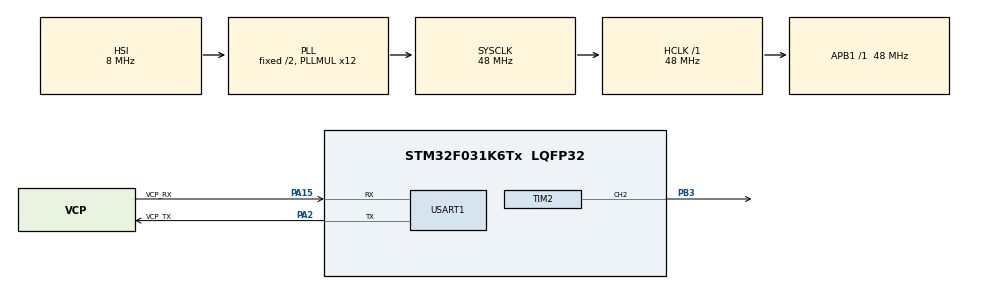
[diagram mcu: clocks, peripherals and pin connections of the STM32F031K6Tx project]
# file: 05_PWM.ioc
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Mcu.Family=STM32F0
NVIC.TIM14_IRQn=true\:0\:0\:false\:false\:true\:true\:true
PA14.GPIO_Label=SWCLK
TIM2.Channel-PWM\ Generation2\ CH2=TIM_CHANNEL_2
RCC.SYSCLKSource=RCC_SYSCLKSOURCE_PLLCLK
ProjectManager.StackSize=0x400
USART1.VirtualMode-Asynchronous=VM_ASYNC
PA13.Signal=SYS_SWDIO
SH.S_TIM2_CH2.0=TIM2_CH2,PWM Generation2 CH2
PA15.GPIO_Label=VCP_RX
ProjectManager.TargetToolchain=TrueSTUDIO
RCC.HCLKFreq_Value=48000000
RCC.AHBFreq_Value=48000000
PF0-OSC_IN.Mode=HSE-External-Clock-Source
board=NUCLEO-F031K6
TIM14.Period=191
PA15.Mode=Asynchronous
RCC.PLLMUL=RCC_PLL_MUL12
VP_TIM2_VS_ClockSourceINT.Mode=Internal
PA14.Mode=Serial_Wire
NVIC.TIM2_IRQn=true\:0\:0\:false\:false\:true\:true\:true
TIM2.Period=99
PA13.Mode=Serial_Wire
Mcu.Name=STM32F031K6Tx
TIM14.Prescaler=10000
PA2.Signal=USART1_TX
PA13.GPIO_Label=SWDIO
PB3.Signal=S_TIM2_CH2
RCC.SYSCLKFreq_VALUE=48000000
Mcu.Package=LQFP32
TIM2.Prescaler=4800
PA2.GPIO_Label=VCP_TX
PA14.Signal=SYS_SWCLK
PA15.Signal=USART1_RX
ProjectManager.HeapSize=0x200
RCC.APB1TimFreq_Value=48000000
PA2.Mode=Asynchronous
VP_TIM14_VS_ClockSourceINT.Mode=Enable_Timer
PF0-OSC_IN.Signal=RCC_OSC_IN
RCC.APB1Freq_Value=48000000

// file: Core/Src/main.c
/* USER CODE BEGIN Header */
/**
  ******************************************************************************
  * @file           : main.c
  * @brief          : Main program body
  ******************************************************************************
  * @attention
  *
  * <h2><center>&copy; Copyright (c) 2020 STMicroelectronics.
  * All rights reserved.</center></h2>
  *
  * This software component is licensed by ST under BSD 3-Clause license,
  * the "License"; You may not use this file except in compliance with the
  * License. You may obtain a copy of the License at:
  *                        opensource.org/licenses/BSD-3-Clause
  *
  ******************************************************************************
  */
/* USER CODE END Header */
#include "main.h"

TIM_HandleTypeDef htim2;
TIM_HandleTypeDef htim14;

UART_HandleTypeDef huart1;

void SystemClock_Config(void);
static void MX_GPIO_Init(void);
static void MX_USART1_UART_Init(void);
static void MX_TIM2_Init(void);
static void MX_TIM14_Init(void);
/* USER CODE BEGIN PFP */
//void HAL_SYSTICK_Callback(void) {
//	static uint8_t InterruptPrescaller = 0;
//	static uint8_t CzyRosnie = 1;
//
//	++InterruptPrescaller;
//
//	if (InterruptPrescaller == 40) {
//		InterruptPrescaller = 0;
//
//		if (Duty == 100) {
//			CzyRosnie = 0;
//		}
//		else if (Duty == 0) {
//			CzyRosnie = 1;
//		}
//
//		if (CzyRosnie == 1) {
//			++Duty;
//		}
//		else if (CzyRosnie == 0) {
//			--Duty;
//		}
//
//		TIM2->CCR2 = Duty;
//	}
//}

////Przerwanie wywolywane z czestotliwoscia 1KHz
//void HAL_SYSTICK_Callback(void) {
//	static uint8_t InterruptPrescaler = 0; // licznik przerwan
//	static uint8_t CzyRosnie = 1; // Flaga kierunku zliczania
//
//	++InterruptPrescaler; // Inkrementacja numeru przerwania
//
//	// Jezeli wywolalo sie 40 przerwanie z rzedu
//	if (InterruptPrescaler == 40) {
//		InterruptPrescaler = 0; // wyzeruj licznik przerwan
//
//		if (Duty == 100) // Jezeli wypelnienie jest rowne 100
//			CzyRosnie = 0; // Zmien kierunek zliczania w dol
//
//		else if (Duty == 0) // Jezeli wypelnienie rowne 0
//			CzyRosnie = 1; // Zmien kierunek zliczania w gore
//
//		if (CzyRosnie) // Jezeli zliczamy w gore
//			++Duty; // Inkrementuj wartosc wypelnienia
//		else//Jezeli zliczamy w dol
//			--Duty; // Dekrementuj wartosc wypelnienia
//	}
//	TIM2->CCR2 = Duty; // Wstawienie wyliczonej wartosci wypelnienia do
//	// rejestru timera odpowiedzialnego za wypelnienie generowanego sygnalu PWM
//}

void HAL_TIM_PeriodElapsedCallback(TIM_HandleTypeDef *htim) {
	static uint8_t Duty = 0;
	static uint8_t CzyRosnie = 1;
	if (htim->Instance == TIM14) {
		if (Duty == 100) {
			CzyRosnie = 0;
		}
		else if (Duty == 0) {
			CzyRosnie = 1;
		}

		if (CzyRosnie == 1) {
			++Duty;
		}
		else if (CzyRosnie == 0) {
			--Duty;
		}

		TIM2->CCR2 = Duty;
	}
}
/* USER CODE END PFP */

int main(void)
{

  /* MCU Configuration--------------------------------------------------------*/

  /* Reset of all peripherals, Initializes the Flash interface and the Systick. */
  HAL_Init();

  /* Configure the system clock */
  SystemClock_Config();

  /* Initialize all configured peripherals */
  MX_GPIO_Init();
  MX_USART1_UART_Init();
  MX_TIM2_Init();
  MX_TIM14_Init();
  /* USER CODE BEGIN 2 */
  HAL_TIM_PWM_Start(&htim2, TIM_CHANNEL_2);
  HAL_TIM_Base_Start_IT(&htim14);
  /* USER CODE END 2 */

  /* Infinite loop */
  while (1)
  {

  }
}

void SystemClock_Config(void)
{
  RCC_OscInitTypeDef RCC_OscInitStruct = {0};
  RCC_ClkInitTypeDef RCC_ClkInitStruct = {0};
  RCC_PeriphCLKInitTypeDef PeriphClkInit = {0};

  /** Initializes the RCC Oscillators according to the specified parameters
  * in the RCC_OscInitTypeDef structure.
  */
  RCC_OscInitStruct.OscillatorType = RCC_OSCILLATORTYPE_HSI;
  RCC_OscInitStruct.HSIState = RCC_HSI_ON;
  RCC_OscInitStruct.HSICalibrationValue = RCC_HSICALIBRATION_DEFAULT;
  RCC_OscInitStruct.PLL.PLLState = RCC_PLL_ON;
  RCC_OscInitStruct.PLL.PLLSource = RCC_PLLSOURCE_HSI;
  RCC_OscInitStruct.PLL.PLLMUL = RCC_PLL_MUL12;
  RCC_OscInitStruct.PLL.PREDIV = RCC_PREDIV_DIV1;
  if (HAL_RCC_OscConfig(&RCC_OscInitStruct) != HAL_OK)
  {
    Error_Handler();
  }
  /** Initializes the CPU, AHB and APB buses clocks
  */
  RCC_ClkInitStruct.ClockType = RCC_CLOCKTYPE_HCLK|RCC_CLOCKTYPE_SYSCLK
                              |RCC_CLOCKTYPE_PCLK1;
  RCC_ClkInitStruct.SYSCLKSource = RCC_SYSCLKSOURCE_PLLCLK;
  RCC_ClkInitStruct.AHBCLKDivider = RCC_SYSCLK_DIV1;
  RCC_ClkInitStruct.APB1CLKDivider = RCC_HCLK_DIV1;

  if (HAL_RCC_ClockConfig(&RCC_ClkInitStruct, FLASH_LATENCY_1) != HAL_OK)
  {
    Error_Handler();
  }
  PeriphClkInit.PeriphClockSelection = RCC_PERIPHCLK_USART1;
  PeriphClkInit.Usart1ClockSelection = RCC_USART1CLKSOURCE_PCLK1;
  if (HAL_RCCEx_PeriphCLKConfig(&PeriphClkInit) != HAL_OK)
  {
    Error_Handler();
  }
}

static void MX_TIM2_Init(void)
{

  TIM_ClockConfigTypeDef sClockSourceConfig = {0};
  TIM_MasterConfigTypeDef sMasterConfig = {0};
  TIM_OC_InitTypeDef sConfigOC = {0};

  htim2.Instance = TIM2;
  htim2.Init.Prescaler = 4800;
  htim2.Init.CounterMode = TIM_COUNTERMODE_UP;
  htim2.Init.Period = 99;
  htim2.Init.ClockDivision = TIM_CLOCKDIVISION_DIV1;
  htim2.Init.AutoReloadPreload = TIM_AUTORELOAD_PRELOAD_DISABLE;
  if (HAL_TIM_Base_Init(&htim2) != HAL_OK)
  {
    Error_Handler();
  }
  sClockSourceConfig.ClockSource = TIM_CLOCKSOURCE_INTERNAL;
  if (HAL_TIM_ConfigClockSource(&htim2, &sClockSourceConfig) != HAL_OK)
  {
    Error_Handler();
  }
  if (HAL_TIM_PWM_Init(&htim2) != HAL_OK)
  {
    Error_Handler();
  }
  sMasterConfig.MasterOutputTrigger = TIM_TRGO_RESET;
  sMasterConfig.MasterSlaveMode = TIM_MASTERSLAVEMODE_DISABLE;
  if (HAL_TIMEx_MasterConfigSynchronization(&htim2, &sMasterConfig) != HAL_OK)
  {
    Error_Handler();
  }
  sConfigOC.OCMode = TIM_OCMODE_PWM1;
  sConfigOC.Pulse = 0;
  sConfigOC.OCPolarity = TIM_OCPOLARITY_HIGH;
  sConfigOC.OCFastMode = TIM_OCFAST_DISABLE;
  if (HAL_TIM_PWM_ConfigChannel(&htim2, &sConfigOC, TIM_CHANNEL_2) != HAL_OK)
  {
    Error_Handler();
  }
  HAL_TIM_MspPostInit(&htim2);

}

static void MX_TIM14_Init(void)
{

  htim14.Instance = TIM14;
  htim14.Init.Prescaler = 10000;
  htim14.Init.CounterMode = TIM_COUNTERMODE_UP;
  htim14.Init.Period = 191;
  htim14.Init.ClockDivision = TIM_CLOCKDIVISION_DIV1;
  htim14.Init.AutoReloadPreload = TIM_AUTORELOAD_PRELOAD_DISABLE;
  if (HAL_TIM_Base_Init(&htim14) != HAL_OK)
  {
    Error_Handler();
  }

}

static void MX_USART1_UART_Init(void)
{

  huart1.Instance = USART1;
  huart1.Init.BaudRate = 38400;
  huart1.Init.WordLength = UART_WORDLENGTH_8B;
  huart1.Init.StopBits = UART_STOPBITS_1;
  huart1.Init.Parity = UART_PARITY_NONE;
  huart1.Init.Mode = UART_MODE_TX_RX;
  huart1.Init.HwFlowCtl = UART_HWCONTROL_NONE;
  huart1.Init.OverSampling = UART_OVERSAMPLING_16;
  huart1.Init.OneBitSampling = UART_ONE_BIT_SAMPLE_DISABLE;
  huart1.AdvancedInit.AdvFeatureInit = UART_ADVFEATURE_NO_INIT;
  if (HAL_UART_Init(&huart1) != HAL_OK)
  {
    Error_Handler();
  }

}

static void MX_GPIO_Init(void)
{

  /* GPIO Ports Clock Enable */
  __HAL_RCC_GPIOF_CLK_ENABLE();
  __HAL_RCC_GPIOA_CLK_ENABLE();
  __HAL_RCC_GPIOB_CLK_ENABLE();

}

void Error_Handler(void)
{
}

/************************ (C) COPYRIGHT STMicroelectronics *****END OF FILE****/
